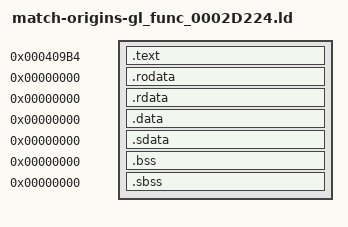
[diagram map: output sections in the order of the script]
/* Standard linker bindings; original USO identity is independently audited. */
SECTIONS {
 .text 0x409b4 : SUBALIGN(4) { *(.text) *(.text.*) }
 .rodata 0x0 : SUBALIGN(4) { *(.rodata) *(.rodata.*) }
 .rdata 0x0 : SUBALIGN(4) { *(.rdata) *(.rdata.*) }
 .data 0x0 : SUBALIGN(4) { *(.data) *(.data.*) }
 .sdata 0x0 : SUBALIGN(4) { *(.sdata) *(.sdata.*) }
 .bss 0x0 : SUBALIGN(4) { *(.bss) *(.bss.*) }
 .sbss 0x0 : SUBALIGN(4) { *(.sbss) *(.sbss.*) }
 /DISCARD/ : { *(.mdebug) *(.reginfo) *(.pdr) *(.comment) *(.MIPS.abiflags) *(.options) }
}
D_00000000 = 0x0;
gl_2D224_init_links = 0x0;
gl_2D224_reset_record = 0x0;
